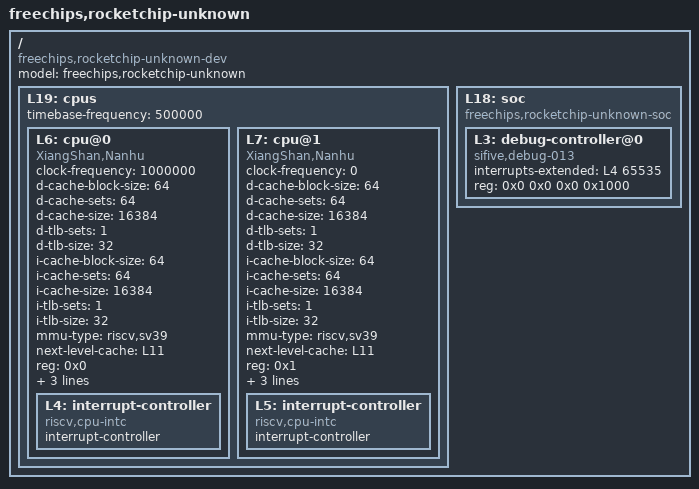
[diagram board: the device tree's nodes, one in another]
/** @file
 Nanhu platform Device Tree

 Copyright (c) 2022, BOSC. All rights reserved.

 SPDX-License-Identifier: BSD-2-Clause-Patent

**/
/dts-v1/;
#include "Nanhu.dtsi"
/ {
	#address-cells = <2>;
	#size-cells = <2>;
	compatible = "freechips,rocketchip-unknown-dev";
	model = "freechips,rocketchip-unknown";
	L19: cpus {
		#address-cells = <1>;
		#size-cells = <0>;
		/*
		 * The rdtime cycle multiplied by 100 is
		 * the cycle frequency (CPU frequency)
		 */
        timebase-frequency = <500000>;//50Khz
		L6: cpu@0 {
			clock-frequency = <1000000>;
			compatible = "XiangShan,Nanhu", "riscv";
			d-cache-block-size = <64>;
			d-cache-sets = <64>;
			d-cache-size = <16384>;
			d-tlb-sets = <1>;
			d-tlb-size = <32>;
			device_type = "cpu";
			i-cache-block-size = <64>;
			i-cache-sets = <64>;
			i-cache-size = <16384>;
			i-tlb-sets = <1>;
			i-tlb-size = <32>;
			mmu-type = "riscv,sv39";
			next-level-cache = <&L11>;
			reg = <0x0>;
			riscv,isa = "rv64imafdc";
			status = "okay";
			timebase-frequency = <500000>;//50Khz
			tlb-split;
			L4: interrupt-controller {
				#interrupt-cells = <1>;
				compatible = "riscv,cpu-intc";
				interrupt-controller;
			};
		};
        L7: cpu@1 {
			clock-frequency = <0>;
			compatible = "XiangShan,Nanhu", "riscv";
			d-cache-block-size = <64>;
			d-cache-sets = <64>;
			d-cache-size = <16384>;
			d-tlb-sets = <1>;
			d-tlb-size = <32>;
			device_type = "cpu";
			i-cache-block-size = <64>;
			i-cache-sets = <64>;
			i-cache-size = <16384>;
			i-tlb-sets = <1>;
			i-tlb-size = <32>;
			mmu-type = "riscv,sv39";
			next-level-cache = <&L11>;
			reg = <0x1>;
			riscv,isa = "rv64imafdc";
			status = "okay";
			timebase-frequency = <500000>;//50Khz
			tlb-split;
			L5: interrupt-controller {
				#interrupt-cells = <1>;
				compatible = "riscv,cpu-intc";
				interrupt-controller;
			};
		};
	};
	L18: soc {
		#address-cells = <2>;
		#size-cells = <2>;
		compatible = "freechips,rocketchip-unknown-soc", "simple-bus";
		ranges;
		L3: debug-controller@0 {
			compatible = "sifive,debug-013", "riscv,debug-013";
			interrupts-extended = <&L4 65535>;
			reg = <0x0 0x0 0x0 0x1000>;
			reg-names = "control";
		};
	};
};
